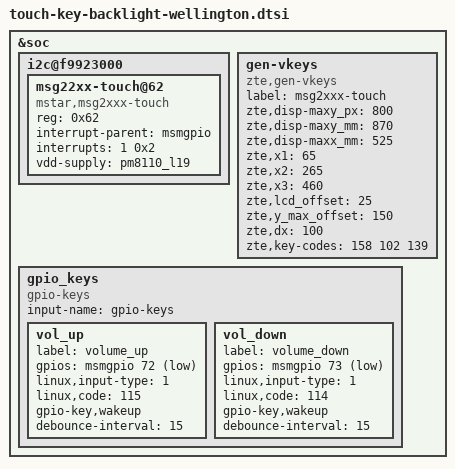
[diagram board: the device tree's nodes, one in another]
//for touchscreen and key and keypad-backlight

&soc {

	i2c@f9923000{		
		// -start-add-20140716001-Jason_Tsai-add-start- 
		// add MSG21xx touchpanel		
		msg22xx-touch@62 {			
		compatible = "mstar,msg2xxx-touch";
		reg = <0x62>;			
		interrupt-parent = <&msmgpio>;
		interrupts = <1 0x2>;			
		vdd-supply = <&pm8110_l19>;			
		//vcc_i2c-supply = <&pm8110_l14>;
		//msg21xx,reset-gpio = <&msmgpio 0 0x00>;
		//msg21xx,irq-gpio = <&msmgpio 1 0x00>;
		};		
		// -end-add-20140716001-Jason_Tsai-add-end- 
		//	
		};
	gen-vkeys {
		compatible = "zte,gen-vkeys";
		label = "msg2xxx-touch";
		zte,disp-maxy_px = <800>;
		zte,disp-maxy_mm = <870>;//0.1mm
		zte,disp-maxx_mm = <525>;//0.1mm
		zte,x1=<65>;
		zte,x2=<265>;
		zte,x3=<460>;
		zte,lcd_offset=<25>;//距离LCD至少2mm 这里再放宽0.5mm
		zte,y_max_offset=<150>;//默认值LCD下边沿到按键下边沿距离估计取大值做余量
		zte,dx=<100>;//标准中X范围为5mm+-1mm取中值*2
		zte,key-codes = <158 102 139>;
	};	
	gpio_keys {
		compatible = "gpio-keys";
		input-name = "gpio-keys";

		vol_up {
			label = "volume_up";
			gpios = <&msmgpio 72 0x1>;
			linux,input-type = <1>;
			linux,code = <115>;
			gpio-key,wakeup;
			debounce-interval = <15>;
		};
		
		vol_down {
			label = "volume_down";
			gpios = <&msmgpio 73 0x1>;
			linux,input-type = <1>;
			linux,code = <114>;
			gpio-key,wakeup;
			debounce-interval = <15>;
		};	
	}; 
	
};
